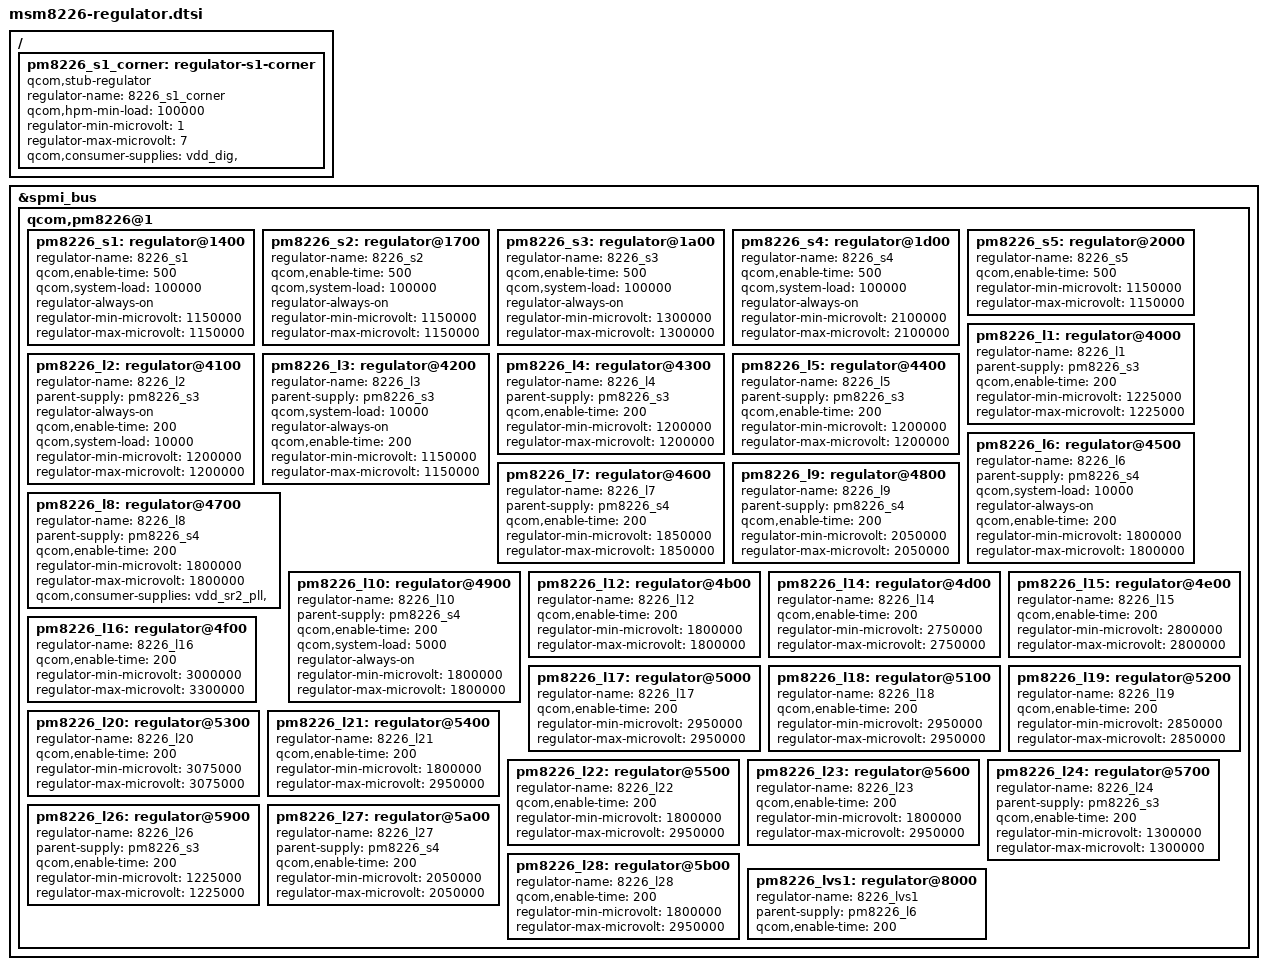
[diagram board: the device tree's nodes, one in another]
/* Copyright (c) 2012-2013, The Linux Foundation. All rights reserved.
 *
 * This program is free software; you can redistribute it and/or modify
 * it under the terms of the GNU General Public License version 2 and
 * only version 2 as published by the Free Software Foundation.
 *
 * This program is distributed in the hope that it will be useful,
 * but WITHOUT ANY WARRANTY; without even the implied warranty of
 * MERCHANTABILITY or FITNESS FOR A PARTICULAR PURPOSE.  See the
 * GNU General Public License for more details.
 */

/* Stub Regulators */

/ {
	pm8226_s1_corner: regulator-s1-corner {
		compatible = "qcom,stub-regulator";
		regulator-name = "8226_s1_corner";
		qcom,hpm-min-load = <100000>;
		regulator-min-microvolt = <1>;
		regulator-max-microvolt = <7>;
		qcom,consumer-supplies = "vdd_dig", "";
	};
};

/* QPNP controlled regulators: */

&spmi_bus {

	qcom,pm8226@1 {

		pm8226_s1: regulator@1400 {
			status = "okay";
			regulator-name = "8226_s1";
			qcom,enable-time = <500>;
			qcom,system-load = <100000>;
			regulator-always-on;
			regulator-min-microvolt = <1150000>;
			regulator-max-microvolt = <1150000>;
		};

		pm8226_s2: regulator@1700 {
			status = "okay";
			regulator-name = "8226_s2";
			qcom,enable-time = <500>;
			qcom,system-load = <100000>;
			regulator-always-on;
			regulator-min-microvolt = <1150000>;
			regulator-max-microvolt = <1150000>;
		};

		pm8226_s3: regulator@1a00 {
			status = "okay";
			regulator-name = "8226_s3";
			qcom,enable-time = <500>;
			qcom,system-load = <100000>;
			regulator-always-on;
			regulator-min-microvolt = <1300000>;
			regulator-max-microvolt = <1300000>;
		};

		pm8226_s4: regulator@1d00 {
			status = "okay";
			regulator-name = "8226_s4";
			qcom,enable-time = <500>;
			qcom,system-load = <100000>;
			regulator-always-on;
			regulator-min-microvolt = <2100000>;
			regulator-max-microvolt = <2100000>;
		};

		pm8226_s5: regulator@2000 {
			status = "okay";
			regulator-name = "8226_s5";
			qcom,enable-time = <500>;
			regulator-min-microvolt = <1150000>;
			regulator-max-microvolt = <1150000>;
		};

		pm8226_l1: regulator@4000 {
			status = "okay";
			regulator-name = "8226_l1";
			parent-supply = <&pm8226_s3>;
			qcom,enable-time = <200>;
			regulator-min-microvolt = <1225000>;
			regulator-max-microvolt = <1225000>;
		};

		pm8226_l2: regulator@4100 {
			status = "okay";
			regulator-name = "8226_l2";
			parent-supply = <&pm8226_s3>;
			regulator-always-on;
			qcom,enable-time = <200>;
			qcom,system-load = <10000>;
			regulator-min-microvolt = <1200000>;
			regulator-max-microvolt = <1200000>;
		};

		pm8226_l3: regulator@4200 {
			status = "okay";
			regulator-name = "8226_l3";
			parent-supply = <&pm8226_s3>;
			qcom,system-load = <10000>;
			regulator-always-on;
			qcom,enable-time = <200>;
			regulator-min-microvolt = <1150000>;
			regulator-max-microvolt = <1150000>;
		};

		pm8226_l4: regulator@4300 {
			status = "okay";
			regulator-name = "8226_l4";
			parent-supply = <&pm8226_s3>;
			qcom,enable-time = <200>;
			regulator-min-microvolt = <1200000>;
			regulator-max-microvolt = <1200000>;
		};

		pm8226_l5: regulator@4400 {
			status = "okay";
			regulator-name = "8226_l5";
			parent-supply = <&pm8226_s3>;
			qcom,enable-time = <200>;
			regulator-min-microvolt = <1200000>;
			regulator-max-microvolt = <1200000>;
		};

		pm8226_l6: regulator@4500 {
			status = "okay";
			regulator-name = "8226_l6";
			parent-supply = <&pm8226_s4>;
			qcom,system-load = <10000>;
			regulator-always-on;
			qcom,enable-time = <200>;
			regulator-min-microvolt = <1800000>;
			regulator-max-microvolt = <1800000>;
		};

		pm8226_l7: regulator@4600 {
			status = "okay";
			regulator-name = "8226_l7";
			parent-supply = <&pm8226_s4>;
			qcom,enable-time = <200>;
			regulator-min-microvolt = <1850000>;
			regulator-max-microvolt = <1850000>;
		};

		pm8226_l8: regulator@4700 {
			status = "okay";
			regulator-name = "8226_l8";
			parent-supply = <&pm8226_s4>;
			qcom,enable-time = <200>;
			regulator-min-microvolt = <1800000>;
			regulator-max-microvolt = <1800000>;
			qcom,consumer-supplies = "vdd_sr2_pll", "";
		};

		pm8226_l9: regulator@4800 {
			status = "okay";
			regulator-name = "8226_l9";
			parent-supply = <&pm8226_s4>;
			qcom,enable-time = <200>;
			regulator-min-microvolt = <2050000>;
			regulator-max-microvolt = <2050000>;
		};

		pm8226_l10: regulator@4900 {
			status = "okay";
			regulator-name = "8226_l10";
			parent-supply = <&pm8226_s4>;
			qcom,enable-time = <200>;
			qcom,system-load = <5000>;
			regulator-always-on;
			regulator-min-microvolt = <1800000>;
			regulator-max-microvolt = <1800000>;
		};

		pm8226_l12: regulator@4b00 {
			status = "okay";
			regulator-name = "8226_l12";
			qcom,enable-time = <200>;
			regulator-min-microvolt = <1800000>;
			regulator-max-microvolt = <1800000>;
		};

		pm8226_l14: regulator@4d00 {
			status = "okay";
			regulator-name = "8226_l14";
			qcom,enable-time = <200>;
			regulator-min-microvolt = <2750000>;
			regulator-max-microvolt = <2750000>;
		};

		pm8226_l15: regulator@4e00 {
			status = "okay";
			regulator-name = "8226_l15";
			qcom,enable-time = <200>;
			regulator-min-microvolt = <2800000>;
			regulator-max-microvolt = <2800000>;
		};

		pm8226_l16: regulator@4f00 {
			status = "okay";
			regulator-name = "8226_l16";
			qcom,enable-time = <200>;
			regulator-min-microvolt = <3000000>;
			regulator-max-microvolt = <3300000>;
		};

		pm8226_l17: regulator@5000 {
			status = "okay";
			regulator-name = "8226_l17";
			qcom,enable-time = <200>;
			regulator-min-microvolt = <2950000>;
			regulator-max-microvolt = <2950000>;
		};

		pm8226_l18: regulator@5100 {
			status = "okay";
			regulator-name = "8226_l18";
			qcom,enable-time = <200>;
			regulator-min-microvolt = <2950000>;
			regulator-max-microvolt = <2950000>;
		};

		pm8226_l19: regulator@5200 {
			status = "okay";
			regulator-name = "8226_l19";
			qcom,enable-time = <200>;
			regulator-min-microvolt = <2850000>;
			regulator-max-microvolt = <2850000>;
		};

		pm8226_l20: regulator@5300 {
			status = "okay";
			regulator-name = "8226_l20";
			qcom,enable-time = <200>;
			regulator-min-microvolt = <3075000>;
			regulator-max-microvolt = <3075000>;
		};

		pm8226_l21: regulator@5400 {
			status = "okay";
			regulator-name = "8226_l21";
			qcom,enable-time = <200>;
			regulator-min-microvolt = <1800000>;
			regulator-max-microvolt = <2950000>;
		};

		pm8226_l22: regulator@5500 {
			status = "okay";
			regulator-name = "8226_l22";
			qcom,enable-time = <200>;
			regulator-min-microvolt = <1800000>;
			regulator-max-microvolt = <2950000>;
		};

		pm8226_l23: regulator@5600 {
			status = "okay";
			regulator-name = "8226_l23";
			qcom,enable-time = <200>;
			regulator-min-microvolt = <1800000>;
			regulator-max-microvolt = <2950000>;
		};

		pm8226_l24: regulator@5700 {
			status = "okay";
			regulator-name = "8226_l24";
			parent-supply = <&pm8226_s3>;
			qcom,enable-time = <200>;
			regulator-min-microvolt = <1300000>;
			regulator-max-microvolt = <1300000>;
		};

		pm8226_l26: regulator@5900 {
			status = "okay";
			regulator-name = "8226_l26";
			parent-supply = <&pm8226_s3>;
			qcom,enable-time = <200>;
			regulator-min-microvolt = <1225000>;
			regulator-max-microvolt = <1225000>;
		};

		pm8226_l27: regulator@5a00 {
			status = "okay";
			regulator-name = "8226_l27";
			parent-supply = <&pm8226_s4>;
			qcom,enable-time = <200>;
			regulator-min-microvolt = <2050000>;
			regulator-max-microvolt = <2050000>;
		};

		pm8226_l28: regulator@5b00 {
			status = "okay";
			regulator-name = "8226_l28";
			qcom,enable-time = <200>;
			regulator-min-microvolt = <1800000>;
			regulator-max-microvolt = <2950000>;
		};

		pm8226_lvs1: regulator@8000 {
			status = "okay";
			regulator-name = "8226_lvs1";
			parent-supply = <&pm8226_l6>;
			qcom,enable-time = <200>;
		};
	};
};
